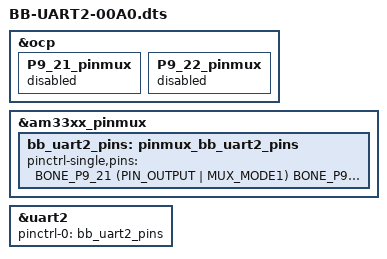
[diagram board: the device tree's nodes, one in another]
/*
 * Copyright (C) 2013 CircuitCo
 *
 * Virtual cape for UART2 on connector pins P9.21 P9.22
 *
 * This program is free software; you can redistribute it and/or modify
 * it under the terms of the GNU General Public License version 2 as
 * published by the Free Software Foundation.
 */

/dts-v1/;
/plugin/;

#include <dt-bindings/board/am335x-bbw-bbb-base.h>
#include <dt-bindings/pinctrl/am33xx.h>

/ {
	/*
	 * Free up the pins used by the cape from the pinmux helpers.
	 */
	fragment@0 {
		target = <&ocp>;
		__overlay__ {
			P9_21_pinmux { status = "disabled"; };	/* uart2_txd */
			P9_22_pinmux { status = "disabled"; };	/* uart2_rxd */
		};
	};

	fragment@1 {
		target = <&am33xx_pinmux>;
		__overlay__ {
			bb_uart2_pins: pinmux_bb_uart2_pins {
				pinctrl-single,pins = <
					BONE_P9_21 (PIN_OUTPUT | MUX_MODE1)	// spi0_d0.uart2_txd
					BONE_P9_22 (PIN_INPUT  | MUX_MODE1)	// spi0_sclk.uart2_rxd
				//	BONE_P8_38 (PIN_OUTPUT | MUX_MODE6)	// lcd_data9.uart2_rtsn
				//	BONE_P8_37 (PIN_INPUT  | MUX_MODE6)	// lcd_data8.uart2_ctsn
				>;
			};
		};
	};

	fragment@2 {
		target = <&uart2>;
		__overlay__ {
			status = "okay";
			pinctrl-names = "default";
			pinctrl-0 = <&bb_uart2_pins>;
		};
	};
};
